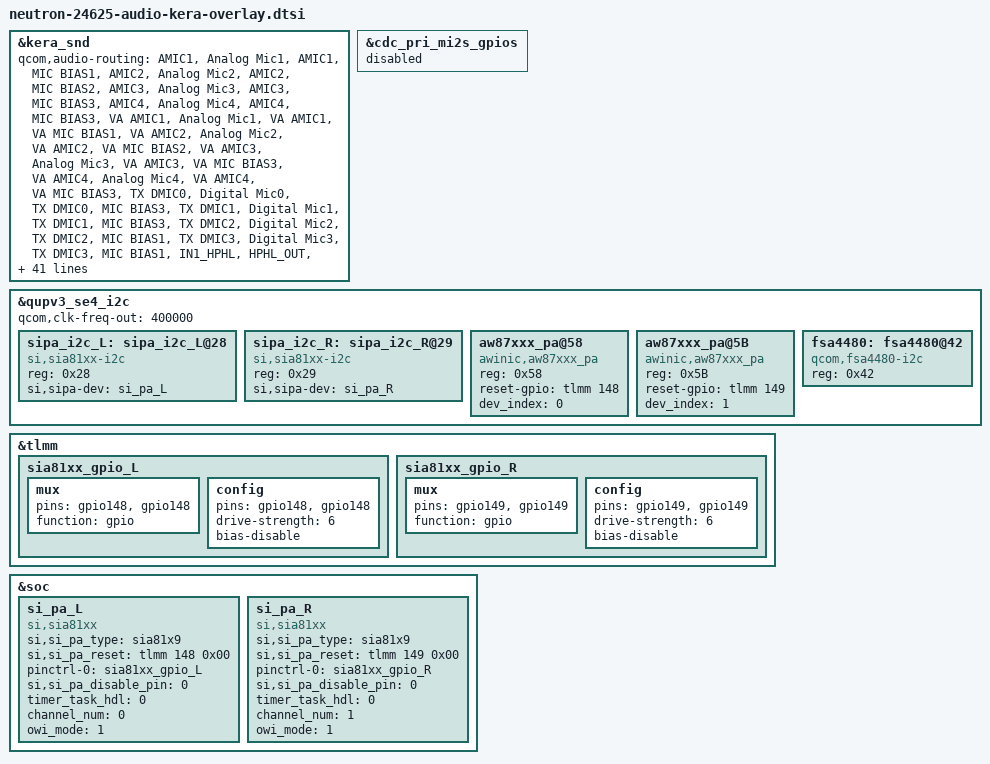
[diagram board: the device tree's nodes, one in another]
&kera_snd {
    qcom,audio-routing =
        "AMIC1", "Analog Mic1",
        "AMIC1", "MIC BIAS1",
        "AMIC2", "Analog Mic2",
        "AMIC2", "MIC BIAS2",
        "AMIC3", "Analog Mic3",
        "AMIC3", "MIC BIAS3",
        "AMIC4", "Analog Mic4",
        "AMIC4", "MIC BIAS3",
        "VA AMIC1", "Analog Mic1",
        "VA AMIC1", "VA MIC BIAS1",
        "VA AMIC2", "Analog Mic2",
        "VA AMIC2", "VA MIC BIAS2",
        "VA AMIC3", "Analog Mic3",
        "VA AMIC3", "VA MIC BIAS3",
        "VA AMIC4", "Analog Mic4",
        "VA AMIC4", "VA MIC BIAS3",
        "TX DMIC0", "Digital Mic0",
        "TX DMIC0", "MIC BIAS3",
        "TX DMIC1", "Digital Mic1",
        "TX DMIC1", "MIC BIAS3",
        "TX DMIC2", "Digital Mic2",
        "TX DMIC2", "MIC BIAS1",
        "TX DMIC3", "Digital Mic3",
        "TX DMIC3", "MIC BIAS1",
        "IN1_HPHL", "HPHL_OUT",
        "IN2_HPHR", "HPHR_OUT",
        "IN3_AUX", "AUX_OUT",
        "RX_TX DEC0_INP", "TX DEC0 MUX",
        "RX_TX DEC1_INP", "TX DEC1 MUX",
        "RX_TX DEC2_INP", "TX DEC2 MUX",
        "RX_TX DEC3_INP", "TX DEC3 MUX",
        "VA SWR_INPUT", "VA_SWR_CLK",
        "VA_AIF1 CAP", "VA_SWR_CLK",
        "VA_AIF2 CAP", "VA_SWR_CLK",
        "VA_AIF3 CAP", "VA_SWR_CLK",
        "VA DMIC0", "Digital Mic0",
        "VA DMIC1", "Digital Mic1",
        "VA DMIC2", "Digital Mic2",
        "VA DMIC3", "Digital Mic3",
        "VA DMIC0", "VA MIC BIAS3",
        "VA DMIC1", "VA MIC BIAS3",
        "VA DMIC2", "VA MIC BIAS1",
        "VA DMIC3", "VA MIC BIAS1";
    qcom,msm-mbhc-hs-mic-max-threshold-mv = <2600>;
    qcom,msm-mbhc-hs-mic-min-threshold-mv = <112>;/* 75*2700/1800 */
    qcom,msm-mbhc-usbc-audio-supported = <1>;
    qcom,msm-mbhc-hphl-swh = <0>;
    qcom,msm-mbhc-gnd-swh = <0>; /* follow bale*/
    oplus,mbhc-headset-micbias-alwayon = <1>;

    qcom,mi2s-audio-intf = <0>;
    qcom,tdm-audio-intf = <0>;
    qcom,pri-mi2s-gpios = <&cdc_pri_mi2s_gpios>;
    swr-haptics-unsupported; // disable qcom haptics
    qcom,wcn-bt = <1>;

    qcom,cdc-dmic01-gpios = <&cdc_dmic01_gpios>;
    qcom,cdc-dmic23-gpios = <&cdc_dmic23_gpios>;
    qcom,cdc-dmic45-gpios = <&cdc_dmic45_gpios>;
    asoc-codec  = <&stub_codec>, <&lpass_cdc>,
               <&wcd9378_codec>;
    asoc-codec-names = "msm-stub-codec.1", "lpass-cdc",
               "wcd9378_codec";
    qcom,wsa-max-devs = <0>;
    qcom,msm_audio_ssr_devs = <&audio_gpr>, <&lpi_tlmm>,
               <&lpass_cdc>;

    oplus,mbhc-headset-micbias-alwayon = <1>;
    oplus,mbhc-check-cross-conn = <1>;

    oplus,pa_manager = <1>;
    oplus,speaker-pa = "sia81xx";
    si,sia81xx-max-num = <2>;
    si,sia81xx-aux-devs = <&si_pa_L>, <&si_pa_R>;
    si,sia81xx-aux-devs-prefix = "SpkrMonoL", "SpkrMonoR";
    fsa4480-i2c-handle = <&fsa4480>;
};

&cdc_pri_mi2s_gpios {
    status = "disabled";
};

&qupv3_se4_i2c {
    status = "ok";
    qcom,clk-freq-out = <400000>;
    sipa_i2c_L: sipa_i2c_L@28{
        compatible = "si,sia81xx-i2c";
        reg = <0x28>;
        si,sipa-dev = <&si_pa_L>;
    };

    sipa_i2c_R: sipa_i2c_R@29{
        compatible = "si,sia81xx-i2c";
        reg = <0x29>;
        si,sipa-dev = <&si_pa_R>;
    };

    aw87xxx_pa@58 {
        compatible = "awinic,aw87xxx_pa";
        reg = <0x58>;
        reset-gpio = <&tlmm 148 0>;
        dev_index = < 0 >;
        //aw-rx-topo-id = <0x1000ff00>;
        //aw-rx-port-id = <0xB030>;
        status = "okay";
    };

    aw87xxx_pa@5B {
        compatible = "awinic,aw87xxx_pa";
        reg = <0x5B>;
        reset-gpio = <&tlmm 149 0>;
        dev_index = < 1 >;
        //aw-rx-topo-id = <0x1000ff00>;
        //aw-rx-port-id = <0xB030>;
        status = "okay";
    };

    fsa4480: fsa4480@42 {
        status = "ok";
        compatible = "qcom,fsa4480-i2c";
        reg = <0x42>;
    };
};

&tlmm {
    sia81xx_gpio_L: sia81xx_gpio_L {
        mux {
            pins = "gpio148", "gpio148";
            function = "gpio";
        };

        config {
            pins = "gpio148", "gpio148";
            drive-strength = <6>;
            bias-disable;
        };
    };

    sia81xx_gpio_R: sia81xx_gpio_R {
        mux {
            pins = "gpio149", "gpio149";
            function = "gpio";
        };

        config {
            pins = "gpio149", "gpio149";
            drive-strength = <6>;
            bias-disable;
        };
    };
};


&soc {
    si_pa_L: si_pa_L{
        compatible = "si,sia81xx";
        si,si_pa_type = "sia81x9";
        si,si_pa_reset = <&tlmm 148 0x00>;
        pinctrl-names = "si_pa_gpio";
        pinctrl-0 = <&sia81xx_gpio_L>;

        si,si_pa_disable_pin = <0>;

        /* the same value share a same task
         * valid value range : 0 ~ 7 */
        timer_task_hdl = <0>;

        channel_num = <0>;
        owi_mode = <1>;
    };

    si_pa_R: si_pa_R{
        compatible = "si,sia81xx";
        si,si_pa_type = "sia81x9";
        si,si_pa_reset = <&tlmm 149 0x00>;
        pinctrl-names = "si_pa_gpio";
        pinctrl-0 = <&sia81xx_gpio_R>;

        si,si_pa_disable_pin = <0>;

        /* the same value share a same task
        * valid value range : 0 ~ 7 */
        timer_task_hdl = <0>;

        channel_num = <1>;
        owi_mode = <1>;
    };
};
